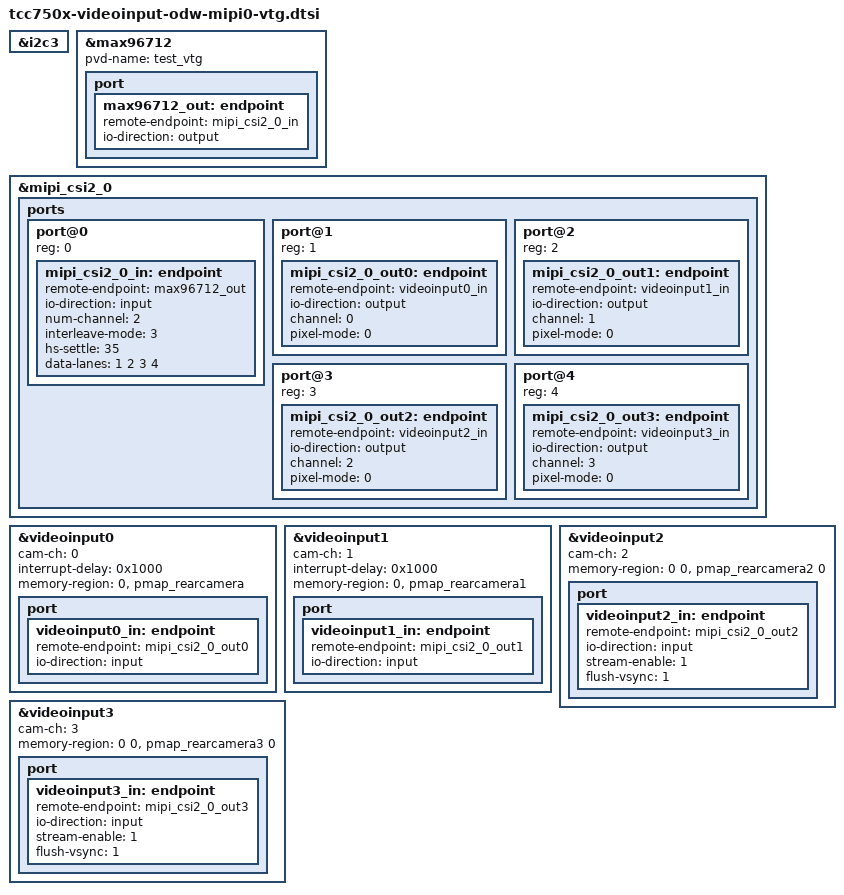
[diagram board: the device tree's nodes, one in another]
// SPDX-License-Identifier: (GPL-2.0-or-later OR MIT)
/*
 * Copyright (C) Telechips Inc.
 */

&i2c3 {
	status = "okay";
};

&max96712 {
	/* deserializer */
	status		= "okay";
	pvd-name	= "test_vtg";

	port {
		max96712_out: endpoint {
			remote-endpoint = <&mipi_csi2_0_in>;
			io-direction	= "output";
		};
	};
};

&mipi_csi2_0 {
	status = "okay";
	ports {
		#address-cells = <1>;
		#size-cells = <0>;
		/*
		 * 0
		 * input port.
		 *
		 * 1 ~ 4
		 * output ports. (1: VC0 ~ 4: VC3)
		 */
		port@0 {
			reg = <0>;
			mipi_csi2_0_in: endpoint {
				remote-endpoint	= <&max96712_out>;
				io-direction	= "input";
				num-channel	= <2>;

				/*
				 * 0: CH0 only, no data interleave
				 * 1: DT only
				 * 2: VC only
				 * 3: VC and DT
				 */
				interleave-mode = <3>;
				hs-settle = <35>;
				data-lanes = <1 2 3 4>;
			};
		};
		port@1 {
			reg = <1>;
			mipi_csi2_0_out0: endpoint {
				remote-endpoint	= <&videoinput0_in>;
				io-direction	= "output";
				channel		= <0>;
				/*
				 * 0: Single pixel mode
				 * 1: Dual pixel mode (RAW8/10/12, YUV422)
				 * 2: Quad pixel mode (RAW8/10/12)
				 * 3: Invalid
				 */
				pixel-mode = <0>;
			};
		};
		port@2 {
			reg = <2>;
			mipi_csi2_0_out1: endpoint {
				remote-endpoint	= <&videoinput1_in>;
				io-direction	= "output";
				channel		= <1>;
				pixel-mode = <0>;
			};
		};
		port@3 {
			reg = <3>;
			mipi_csi2_0_out2: endpoint {
				remote-endpoint	= <&videoinput2_in>;
				io-direction	= "output";
				channel		= <2>;
				pixel-mode = <0>;
			};
		};
		port@4 {
			reg = <4>;
			mipi_csi2_0_out3: endpoint {
				remote-endpoint	= <&videoinput3_in>;
				io-direction	= "output";
				channel		= <3>;
				pixel-mode = <0>;
			};
		};
	};
};

&videoinput0 {
	status		= "okay";
	cam-ch		= <0>;
	interrupt-delay = <0x1000>;
	/* memory-region
	 *  - [0]: parking guideline
	 *  - [1]: preview
	 */
	memory-region	= <0
			   &pmap_rearcamera>;


	port {
		videoinput0_in: endpoint {
			remote-endpoint	= <&mipi_csi2_0_out0>;
			io-direction	= "input";
		};
	};
};

&videoinput1 {
	status		= "okay";
	cam-ch		= <1>;
	interrupt-delay = <0x1000>;
	/* memory-region
	 *  - [0]: parking guideline
	 *  - [1]: preview
	 */
	memory-region	= <0
			   &pmap_rearcamera1>;
	port {
		videoinput1_in: endpoint {
			remote-endpoint	= <&mipi_csi2_0_out1>;
			io-direction	= "input";
		};
	};
};

&videoinput2 {
	status		= "okay";
	cam-ch		= <2>;
	/* memory-region
	 *  - [0]: parking guideline
	 *  - [1]: deinterlacing by viqe
	 *  - [2]: preview
	 *  - [3]: last frame
	 */
	memory-region	= <0
			   0
			   &pmap_rearcamera2
			   0>;
	port {
		videoinput2_in: endpoint {
			remote-endpoint	= <&mipi_csi2_0_out2>;
			io-direction	= "input";
			stream-enable	= <1>;	// VIN_CTRL.SE
			flush-vsync	= <1>;	// VIN_MISC.FVS
		};
	};
};

&videoinput3 {
	status		= "okay";
	cam-ch		= <3>;
	/* memory-region
	 *  - [0]: parking guideline
	 *  - [1]: deinterlacing by viqe
	 *  - [2]: preview
	 *  - [3]: last frame
	 */
	memory-region	= <0
			   0
			   &pmap_rearcamera3
			   0>;
	port {
		videoinput3_in: endpoint {
			remote-endpoint	= <&mipi_csi2_0_out3>;
			io-direction	= "input";
			stream-enable	= <1>;	// VIN_CTRL.SE
			flush-vsync	= <1>;	// VIN_MISC.FVS
		};
	};
};
